# MMCSD0_COMMON_0_CTL_CFG register map
Vendor: Texas Instruments
Registers are 16-bit, read-write, reset 0x0 unless marked. A register's access mark holds for its fields unless they carry their own. Offsets are as the file gives them; [hi:lo] are bit positions; 'fields as' and 'values as' point back to an identical list.

## MMCSD0_COMMON_0_CTL_CFG (part 2 of 3)
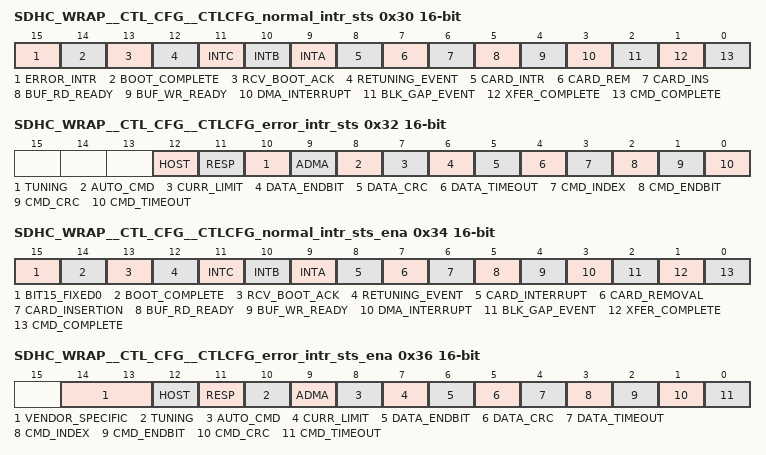
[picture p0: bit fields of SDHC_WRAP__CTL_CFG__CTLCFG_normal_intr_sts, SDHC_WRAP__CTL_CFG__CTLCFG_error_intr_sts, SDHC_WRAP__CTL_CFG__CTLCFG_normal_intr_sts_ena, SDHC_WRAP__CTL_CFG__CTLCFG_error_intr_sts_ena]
0x30 SDHC_WRAP__CTL_CFG__CTLCFG_normal_intr_sts access not given
  [15] ERROR_INTR ro — If any of the bits in the Error Interrupt Status Register are set, then this bit is set. Therefore the HD can test for an error by checking this bit first. In UHS-II mode is enabled, if any of the bits in the UHS-II Error Interrupt Status register are set, this bit is also set. '0' No error '1' Error
  [14] BOOT_COMPLETE — This status is set if the boot operation gets terminated. '0' Boot operation is not terminated '1' Boot operation is terminated (access R/W1TC)
  [13] RCV_BOOT_ACK — This status is set if the boot acknowledge is received from device. '0' Boot ack not recieved '1' Boot ack is recieved (access R/W1TC)
  [12] RETUNING_EVENT ro — This status is set if Re-Tuning Request in the Present State register changes from 0 to 1. Host Controller requests Host Driver to perform re-tuning for next data transfer. Current data transfer [not large block count] can be completed without re-tuning.In UHS-II mode, this bit is not effective '0' Re-tuning not required '1' Re-tuning should be performed
  [11] INTC ro — This status is set if INT_C is enabled and INT_C# pin is in low level. Writing this bit to 1 does not clear this bit. It is cleared by resetting the INT_C interrupt factor.
  [10] INTB ro — This status is set if INT_B is enabled and INT_B# pin is in low level. Writing this bit to 1 does not clear this bit. It is cleared by resetting the INT_B interrupt factor.
  [9] INTA ro — This status is set if INT_A is enabled and INT_A# pin is in low level. Writing this bit to 1 does not clear this bit. It is cleared by resetting the INT_A interrupt factor. NOTE : INT_A, INT_B, and INT_C are to be implemented based on the Application Requirements. By default these are not implemented as there is no specific requirement from Customers.
  [8] CARD_INTR ro — When this status has been set and the Host Driver needs to start this interrupt service, Card Interrupt Status Enable in the Normal Interrupt Status Enable register may be set to 0 in order to clear the card interrupt status latched in the Host Controller and to stop driv-ing the interrupt signal to the Host System.After completion of the card interrupt service [It should reset interrupt factors in the SD card and the interrupt signal may not be asserted],set Card Interrupt Status Enable to 1 and start sampling the interrupt signal again. Writing this bit to 1 does not clear this bit. It is cleared by resetting the SD card interrupt fac-tor. [1] DAT[1] Interrupt Input in SD Mode In 1-bit mode, the Host Controller shall detect the Card Interrupt without SD Clock to support wakeup. In 4-bit mode, the card interrupt sig-nal is sampled during the interrupt cycle, so there are some sample delays between the interrupt signal from the SD card and the inter-rupt to the Host System. Interrupt detected by DAT[1] is supported when there is a card per slot. In case of UHS-I mode, switching time of Interrupt Period is relaxed for 2 clock cycles. Then Host Controller needs to delay start of interrupt sampling at least 2 clocks and should sample interrupt while Interrupt Period is sta-ble. [2] DAT[2] Interrupt Input in UHS-II Mode When Card Inserted in the Present State reg-ister and SD Bus Power for VDD1 in the Power Control register are set to 1, Host Con-troller configures DAT[2] as Interrupt Input and enables pull-up of DAT[2]. DAT[2] interrupt is asynchronous to RCLK, low level sensitive and 3.3V signal level. DAT[2] interrupt is masked by setting Card Interrupt Status Enable to 0 in the Normal Interrupt register.When either Card Inserted or SD Bus Power for VDD1 is set to 0, Host Controller sets DAT[2] to low. Only point to point connection is allowed between Host and Card. [3] INT MSG in UHS-II Mode INT MSG is enabled by setting INT MSG Enable in the UHS-II Device Select register. DAT[2] and INT MSG interrupt sources are ORed and indicated to Card Interrupt. If any bit in the UHS-II Device Interrupt Status regis- ter is set to 1, INT MSG interrupt is generated. INT MSG interrupt is cleared by writing a cor-respondent bit to 1 in the UHS-II Device Inter-rupt Status register. Masking DAT[2] interrupt also disables INT MSG interupt due to Card Interrupt Status Enable is set to 0. SDIO Ver-sion 4.00 does not support INT MSG. '0' No Card Interrupt '1' Generate Card Interrupt
  [7] CARD_REM — This status is set if the Card Inserted in the Present State register changes from 1 to 0. When the HD writes this bit to 1 to clear this status the status of the Card Inserted in the Present State register should be confirmed. Because the card detect may possibly be changed when the HD clear this bit an Interrupt event may not be generated. '0' Card State Stable or Debouncing '1' Card Removed (access R/W1TC)
  [6] CARD_INS — This status is set if the Card Inserted in the Present State register changes from 0 to 1.When the HD writes this bit to 1 to clear this status the status of the Card Inserted in the Present State register should be confirmed. Because the card detect may possibly be changed when the HD clear this bit an Interrupt event may not be generated. '0' Card State Stable or Debouncing '1' Card Inserted (access R/W1TC)
  [5] BUF_RD_READY — This status is set if the Buffer Read Enable changes from 0 to 1. Buffer Read Ready is set to 1 for every CMD19 execution in tuning procedure.In UHS-II mode, this bit is set at FC [Flow Control] unit basis. '0' Not ready to read buffer, '1' Ready to read buffer (access R/W1TC)
  [4] BUF_WR_READY — This status is set if the Buffer Write Enable changes from 0 to 1.In UHS-II mode, this bit is set at FC [Flow Control] unit basis. '0' Not ready to write to buffer, '1' Ready to write to buffer (access R/W1TC)
  [3] DMA_INTERRUPT — This status is set if the HC detects the Host DMA Buffer Boundary in the Block Size regiser. '0' No DMA Interrupt '1' DMA Interrupt is generated (access R/W1TC)
  [2] BLK_GAP_EVENT — If the Stop At Block Gap Request in the BlockGap Control Register is set, this bit is set. Read Transaction: This bit is set at the falling edge of the DAT Line Active Status [When the transaction is stopped at SD Bus timing. The Read Wait must be supported inorder to use this function]. Write Transaction: This bit is set at the falling edge of Write Transfer Active Status [After getting CRC status at SD Bus timing]. In UHS-II mode, this bit is set at FC [Flow Control] unit basis. '0' No Block Gap Event '1' Transaction stopped at Block Gap (access R/W1TC)
  [1] XFER_COMPLETE — This bit is set when a read / write transaction is completed. SD Mode Read Transaction: This bit is set at the falling edge of Read Transfer Active Status. There are two cases in which the Interrupt is generated. The first is when a data transfer is completed as specified by data length [After the last data has been read to the Host Sys- tem]. The second is when data has stopped at the block gap and completed the data transfer by setting the Stop At Block Gap Request in the Block Gap Control Register [After valid data has been read to the Host System]. Write Transaction: This bit is set at the falling edge of the DAT Line Active Status. There are two cases in which the Interrupt is generated. The first is when the last data is written to the card as specified by data length and Busy signal is released. The second is when data transfers are stopped at the block gap by setting Stop At Block Gap Request in the Block Gap Control Register and data transfers completed. [After valid data is written to the SD card and the busy signal is released]. Note: Transfer Complete has higher priority than Data Time-out Error. If both bits are set to 1, the data transfer can be considered complete. Note: While performing tuning procedure [Execute Tuning is set to 1], Transfer Complete is not set to 1 Command with Busy: This bit is set when busy is de-asserted. Refer to DAT Line Active and Command Inhibit[DAT] in the Present State register.UHS-I mode While performing tuning procedure [Execute Tuning is set to 1], Transfer Complete is not set to 1. '0' No Data Transfer Complete, '1' Data Transfer Complete UHS-II Mode This interrupt is generated in following twocases: [a] EBSY Completion [for EBSY supported commands] When EBSY Wait in the UHS-II Transfer Mode register is set to 1, this bit is set when EBSY packet has been received, and all valid data have been sent to system memory in case of read operation. [b] Stop and Continue during DCMD Data Transfer When Stop At Block Gap Request in the Block Gap Control register is set to 1 and data transfer is stopped at the Flow Control. Following is for both SD mode and UHS-II mode. The table below shows that Transfer Com-plete has higher priority than Data Timeout Error. If both bits are set to 1, execution of a command can be considered to be completed. 1 - Command execution is completed 0 - Not complete (access R/W1TC)
  [0] CMD_COMPLETE — SD Mode This bit is set when we get the end bit of the command response [Except Auto CMD12 and Auto CMD23] Note: Command Time-out Error has higher priority than Command Complete. If both are set to 1, it can be considered that the response was not received correctly. Version 4.00 defines response check function for R1 and R5. If Response Interrupt Disable in the Transfer Mode register is set to 1, gen-eration of this interrupt is prohibited regardless of Command Complete Signal Enable. UHS-II Mode If Response Interrupt Disable is set to 0 in the UHS-II Transfer Mode register, this interrupt is generated when response packet is received.If Response Interrupt Disable is set to 1 in the UHS-II Transfer Mode register, generation of this interrupt is prohibited regardless of Com-mand Complete Signal Enable. '0' No Command Complete, '1' Command Complete (access R/W1TC)
0x32 SDHC_WRAP__CTL_CFG__CTLCFG_error_intr_sts access not given
  [12] HOST — Occurs when detecting ERROR in m_hresp[dma transaction] (access R/W1TC)
  [11] RESP — Host Controller Version 4.00 supports response error check function to avoid overhead of response error check by Host Driver during DMA execution. If Response Error Check Enable is set to 1 in the Transfer Mode register, Host Controller Checks R1 or R5 response. If an error is detected in a response, this bit is set to 1.If Response Error Check Enable is set to 1 in the Transfer Mode register, Host Controller Checks R1 or R5 response. (access R/W1TC)
  [10] TUNING — This bit is set when an unrecoverable error is detected in a tuning circuit except during tuning procedure [Occurrence of an error during tuning procedure is indicated by Sampling Select]. By detecting Tuning Error, Host Driver needs to abort a command executing and perform tuning.To reset tuning circuit, Sampling Clock shall be set to 0 before executing tuning procedure. The Tuning Error is higher priority than the other error interrupts generated during data transfer. By detecting Turning Error, the Host Driver should discard data transferred by a current read/write command and retry data transfer after the Host Controller retrieved from tuning circuit error. (access R/W1TC)
  [9] ADMA — This bit is set when the Host Controller detects errors during ADMA based data transfer. The state of the ADMA at an error occurrence is saved in the ADMA Error Status Register. (access R/W1TC)
  [8] AUTO_CMD — Auto CMD12 and Auto CMD23 use this error status.This bit is set when detecting that any of the bits D00 to D05 in Auto CMD Error Status register has changed from 0 to 1. D07 is effective in case of Auto CMD12. Auto CMD Error Status register is valid while this bit is set to 1 and may be cleared with clearing of this bit [another implementation is also allowed]. (access R/W1TC)
  [7] CURR_LIMIT — By setting the SD Bus Power bit in the Power Control Register, the HC is requested to supply power for the SD Bus. If the HC supports the Current Limit Function, it can be protected from an Illegal card by stopping power supply to the card in which case this bit indicates a failure status. Reading 1 means the HC is not supplying power to SD card due to some failure. Reading 0 means that the HC is supplying power and no error has occurred. This bit shall always set to be 0, if the HC does not support this function. (access R/W1TC)
  [6] DATA_ENDBIT — Occurs when detecting 0 at the end bit position of read data which uses the DAT line or the end bit position of the CRC status. (access R/W1TC)
  [5] DATA_CRC — Occurs when detecting CRC error when transferring read data which uses the DAT line or when detecting the Write CRC Status having a value of other than 010. (access R/W1TC)
  [4] DATA_TIMEOUT — Occurs when detecting one of following timeout conditions: 1. Busy Timeout for R1b, R5b type. 2. Busy Timeout after Write CRC status 3. Write CRC status Timeout 4. Read Data Timeout. (access R/W1TC)
  [3] CMD_INDEX — Occurs if a Command Index error occurs in the Command Response. (access R/W1TC)
  [2] CMD_ENDBIT — Occurs when detecting that the end bit of a command response is 0. (access R/W1TC)
  [1] CMD_CRC — Command CRC Error is generated in two cases. 1. If a response is returned and the Command Time-out Error is set to 0, this bit is set to 1 when detecting a CRT error in the command response 2. The HC detects a CMD line conflict by monitoring the CMD line when a command is issued. If the HC drives the CMD line to 1 level, but detects 0 level on the CMD line at the next SDCLK edge, then the HC shall abort the command [Stop driving CMD line] and set this bit to 1. The Command Timeout Error shall also be set to 1 to distinguish CMD line conflict. (access R/W1TC)
  [0] CMD_TIMEOUT — Occurs only if the no response is returned within 64 SDCLK cycles from the end bit of the command. If the HC detects a CMD line conflict, in which case Command CRC Error shall also be set. This bit shall be set without waiting for 64 SDCLK cycles because the command will be aborted by the HC. (access R/W1TC)
0x34 SDHC_WRAP__CTL_CFG__CTLCFG_normal_intr_sts_ena access per field
  [15] BIT15_FIXED0 ro — The HC shall control error Interrupts using the Error Interrupt Status Enable register.
  [14] BOOT_COMPLETE rw — '0' Masked '1' Enabled
  [13] RCV_BOOT_ACK rw — '0' Masked '1' Enabled
  [12] RETUNING_EVENT rw — 0 - Masked 1 - Enabled
  [11] INTC rw — If this bit is set to 0, the Host Controller shall clear the interrupt request to the System. The Host Driver may clear this bit before servicing the INT_C and may set this bit again after all interrupt requests to INT_C pin are cleared to prevent inadvertent interrupts.
  [10] INTB rw — If this bit is set to 0, the Host Controller shall clear the interrupt request to the System. The Host Driver may clear this bit before servicing the INT_B and may set this bit again after all interrupt requests to INT_B pin are cleared to prevent inadvertent interrupts.
  [9] INTA rw — If this bit is set to 0, the Host Controller shall clear the interrupt request to the System. The Host Driver may clear this bit before servicing the INT_A and may set this bit again after all interrupt requests to INT_A pin are cleared to prevent inadvertent interrupts.
  [8] CARD_INTERRUPT rw — If this bit is set to 0, the HC shall clear Interrupt request to the System. The Card Interrupt detection is stopped when this bit is cleared and restarted when this bit is set to 1. The HD may clear the Card Interrupt Status Enable before servicing the Card Interrupt and may set this bit again after all Interrupt requests from the card are cleared to prevent inadvertent Interrupts. By setting this bit to 0, interrupt input should be masked by implementation so that the interrupt Input is not affected by external signal in any state [ex. floating].
  [7] CARD_REMOVAL rw — '0' Masked '1' Enabled
  [6] CARD_INSERTION rw — '0' Masked '1' Enabled
  [5] BUF_RD_READY rw — '0' Masked '1' Enabled
  [4] BUF_WR_READY rw — '0' Masked '1' Enabled
  [3] DMA_INTERRUPT rw — '0' Masked, '1' Enabled
  [2] BLK_GAP_EVENT rw — '0' Masked '1' Enabled
  [1] XFER_COMPLETE rw — '0' Masked '1' Enabled
  [0] CMD_COMPLETE rw — '0' Masked '1' Enabled
0x36 SDHC_WRAP__CTL_CFG__CTLCFG_error_intr_sts_ena
  [14:13] VENDOR_SPECIFIC
  [12] HOST — '0' Masked '1' Enabled
  [11] RESP — '0' Masked '1' Enabled
  [10] TUNING — '0' Masked '1' Enabled
  [9] ADMA — '0' Masked '1' Enabled
  [8] AUTO_CMD — '0' Masked '1' Enabled
  [7] CURR_LIMIT — '0' Masked '1' Enabled
  [6] DATA_ENDBIT — '0' Masked '1' Enabled
  [5] DATA_CRC — '0' Masked '1' Enabled
  [4] DATA_TIMEOUT — '0' Masked '1' Enabled
  [3] CMD_INDEX — '0' Masked '1' Enabled
  [2] CMD_ENDBIT — '0' Masked '1' Enabled
  [1] CMD_CRC — '0' Masked '1' Enabled
  [0] CMD_TIMEOUT — '0' Masked '1' Enabled
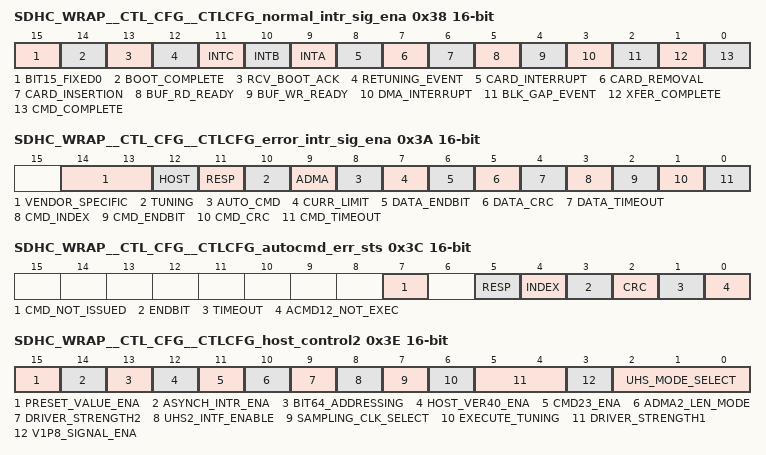
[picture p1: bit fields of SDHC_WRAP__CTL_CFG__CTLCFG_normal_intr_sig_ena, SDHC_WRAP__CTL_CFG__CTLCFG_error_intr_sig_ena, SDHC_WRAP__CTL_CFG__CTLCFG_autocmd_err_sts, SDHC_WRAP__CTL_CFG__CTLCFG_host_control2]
0x38 SDHC_WRAP__CTL_CFG__CTLCFG_normal_intr_sig_ena access per field
  [15] BIT15_FIXED0 ro — The HD shall control error Interrupts using the Error Interrupt Signal Enable register.
  [14] BOOT_COMPLETE rw — '0' Masked '1' Enabled
  [13] RCV_BOOT_ACK rw — '0' Masked '1' Enabled
  [12] RETUNING_EVENT rw — '0' Masked '1' Enabled
  [11] INTC rw — '0' Masked '1' Enabled
  [10] INTB rw — '0' Masked '1' Enabled
  [9] INTA rw — '0' Masked '1' Enabled
  [8] CARD_INTERRUPT rw — '0' Masked '1' Enabled
  [7] CARD_REMOVAL rw — '0' Masked '1' Enabled
  [6] CARD_INSERTION rw — '0' Masked '1' Enabled
  [5] BUF_RD_READY rw — '0' Masked '1' Enabled
  [4] BUF_WR_READY rw — '0' Masked '1' Enabled
  [3] DMA_INTERRUPT rw — '0' Masked '1' Enabled
  [2] BLK_GAP_EVENT rw — '0' Masked '1' Enabled
  [1] XFER_COMPLETE rw — '0' Masked '1' Enabled
  [0] CMD_COMPLETE rw — '0' Masked '1' Enabled
0x3A SDHC_WRAP__CTL_CFG__CTLCFG_error_intr_sig_ena
  fields as SDHC_WRAP__CTL_CFG__CTLCFG_error_intr_sts_ena
0x3C SDHC_WRAP__CTL_CFG__CTLCFG_autocmd_err_sts ro
  [7] CMD_NOT_ISSUED — Setting this bit to 1 means CMD_wo_DAT is not executed due to an Auto CMD12 error [D04- D01] in this register. This bit is set to 0 when Auto CMD Error is generated by Auto CMD23.
  [5] RESP — This bit is set when Response Error Check Enable in the Transfer Mode register is set to 1 and an error is detected in R1 response of either Auto CMD12 or Auto CMD23. This status should be ignored if any bit of D00 to D04 is set to 1.
  [4] INDEX — Occurs if the Command Index error occurs in response to a command.
  [3] ENDBIT — Occurs when detecting that the end bit of command response is 0.
  [2] CRC — Occurs when detecting a CRC error in the command response.
  [1] TIMEOUT — Occurs if the no response is returned within 64 SDCLK cycles from the end bit of the command.If this bit is set to 1, the other error status bits [D04 - D02] are meaningless.
  [0] ACMD12_NOT_EXEC — If memory multiple block data transfer is not started due to command error, this bit is not set because it is not necessary to issue Auto CMD12. Setting this bit to 1 means the HC cannot issue Auto CMD12 to stop memory multiple block transfer due to some error. If this bit is set to 1, other error status bits [D04 - D01] are meaningless. This bit is set to 0 when Auto CMD Error is generated by Auto CMD23
0x3E SDHC_WRAP__CTL_CFG__CTLCFG_host_control2
  [15] PRESET_VALUE_ENA — Host Controller Version 3.00 supports this bit. As the operating SDCLK frequency and I/O driver strength depend on the Host System implementation, it is difficult to determine these parameters in the Standard Host Driver. When Preset Value Enable is set to automatic. This bit enables the functions defined in the Preset Value registers. If this bit is set to 0, SDCLK Frequency Select, Clock Generator Select in the Clock Control register and Driver Strength Select in Host Control 2 register are set by Host Driver. If this bit is set to 1, SDCLK Frequency Select, Clock Generator Select in the Clock Control register and Driver Strength Select in Host Control 2 register are set by Host Controller as specified in the Preset Value registers.
  [14] ASYNCH_INTR_ENA — This bit can be set to 1 if a card support asynchronous interrupt and Asynchronous Interrupt Support is set to 1 in the Capabilities register. Asynchronous interrupt is effective when DAT[1] interrupt is used in 4-bit SD mode [and zero is set to Interrupt Pin Select in the Shared Bus Control register]. If this bit is set to 1, the Host Driver can stop the SDCLK during asynchronous interrupt period to save power. During this period, the Host Controller continues to deliver Card Interrupt to the host when it is asserted by the Card.
  [13] BIT64_ADDRESSING — This field is effective when Host Version 4.00 Enable is set to 1. Host Controller selects either of 32-bit or 64-bit addressing modes to access system memory. Whether 32-bit or 64-bit is determined by OS installed in a host system. Host Driver sets this bit depends on addressing mode of installed OS. Refer to 64-bit System Address Support in the Capabilities register. .
  [12] HOST_VER40_ENA — This bit selects either Version 3.00 compatible mode or Ver4.mode. In Version 4.00, support of 64-bit System Addressing is modified. All DMAs support 64-bit System Addressing. UHS-II supported Host Driver shall enable this bit. In Version 4.10, supported 32-bit Block Count for all operations. Functions of following fields are modified. SDMA Address SDMA uses ADMA System Address register [05Fh-058h] instead of SDMA System Address register [Offset 003-000h] ADMA2 / ADMA3 Selection ADMA3 is selected by DMA Select in the Host Control 1 regis-ter. 64bit ADMA Descriptor Size 128bit descriptor is used instead of 96-bit descriptor when 64-bit Addressing is set to 1. Selection of 32-bit / 64-bit System Addressing Either 32-bit or 64-bit system addressing is selected by 64-bit Addressing bit in this register instead of DMA Select in the Host Control 1 register. 32-bit Block Count SDMA System Address register [003h-000h] is modified to 32-bit Block Count register.
  [11] CMD23_ENA — In memory card initialization, Host Driver Version 4.10 checks whether card supports CMD23 by checking a bit SCR[33]. If the card supports CMD23 [SCR[33]=1], this bit is set to 1. This bit is used to select Auto CMD23 or Auto CMD12 for ADMA3 datatransfer. Refer to Auto CMD Enable in the Transfer Mode regis-ter.
  [10] ADMA2_LEN_MODE — This bit selects one of ADMA2 Length Modes either 16-bit or 26-bit.
  [9] DRIVER_STRENGTH2 — This is the programmed Drive STrength output and Bit[2] of the sdhccore_drivestrength value.
  [8] UHS2_INTF_ENABLE — This bit is used to enable UHS-II Interface. Before trying to start UHS-II initialization, this bit shall be set to 1. Before trying to start SD mode initialization, this bit shall be set to 0. This bit is used to enable UHS-II IF Detection, Lane Synchroni-zation and In Dormant State in the Present State register, and to select clock source of either SD mode or UHS-II mode. Host Controller shall not leave unused SD 4-bit Interface lines [CLK, CMD and DAT[3:2]] floating in UHS-II mode by using pull-up or driving to low. When DAT[2] is used as interrupt input in UHS-II mode, DAT[2] of Host Controller is set to input and then DAT[2] of SDIO card is set to output to avoid conflict. '0' 4-bit SD Interface enabled '1' UHS-II Interface enabled
  [7] SAMPLING_CLK_SELECT — This bit is set by tuning procedure when Execute Tuning is cleared. Writing 1 to this bit is meaningless and ignored. Setting 1 means that tuning is completed successfully and setting 0 means that tuning is failed. Host Controller uses this bit to select sampling clock to receive CMD and DAT. This bit is cleared by writing 0. Change of this bit is not allowed while the Host Controller is receiving response or a read data block.
  [6] EXECUTE_TUNING — This bit is set to 1 to start tuning procedure and automatically cleared when tuning procedure is completed. The result of tuning is indicated to Sampling Clock Select. Tuning procedure is aborted by writing 0 for more detail about tuning procedure. '0' Not Tuned or Tuning Completed '1' Execute Tuning
  [5:4] DRIVER_STRENGTH1 — Host Controller output driver in 1.8V signaling is selected by this bit. In 3.3V signaling, this field is not effective. This field can be set depends on Driver Type A, C and D support bits in the Capabilities register. This bit depends on setting of Preset Value Enable. If Preset Value Enable = 0, this field is set by Host Driver. If Preset Value Enable = 1, this field is automatically set by a value specified in the one of Preset Value registers.
  [3] V1P8_SIGNAL_ENA — This bit controls voltage regulator for I/O cell. 3.3V is supplied to the card regardless of signaling voltage. Setting this bit from 0 to 1 starts changing signal voltage from 3.3V to 1.8V. 1.8V regulator output shall be stable within 5ms. Host Controller clears this bit if switching to 1.8V signaling fails. Clearing this bit from 1 to 0 starts changing signal voltage from 1.8V to 3.3V. 3.3V regulator output shall be stable within 5ms. Host Driver can set this bit to 1 when Host Controller supports 1.8V signaling [One of support bits is set to 1: SDR50, SDR104 or DDR50 in the Capabilities register] and the card or device supports UHS-I. '0' 3.3V Signalling, '1' 1.8V Signalling
  [2:0] UHS_MODE_SELECT — This field is used to select one of UHS-I modes or UHS-II mode.In case of UHS-I mode, this field is effective when 1.8V Signal-ing Enable is set to 1. In case of UHS-II mode, 1.8V Signaling Enable shall be set to 0. Setting of this field is used to select one of preset values in UHS-I or UHS-II mode. If Preset Value Enable in the Host Control 2 register is set to 1,Host Controller sets SDCLK/RCLK Frequency Select, Clock Generator Select in the Clock Control register and Driver Strength Select according to Preset Value registers. In this case, one of preset value registers is selected by this field. Host Driver needs to reset SD Clock Enable before changing this field to avoid generating clock glitch. After setting this field, Host Driver sets SD Clock Enable again. When SDR50, SDR104 or DDR50 is selected for SDIO card, interrupt detection at the block gap shall not be used. Read Wait timing is changed for these modes. Refer to the SDIO Specification Version 3.00 for more detail.
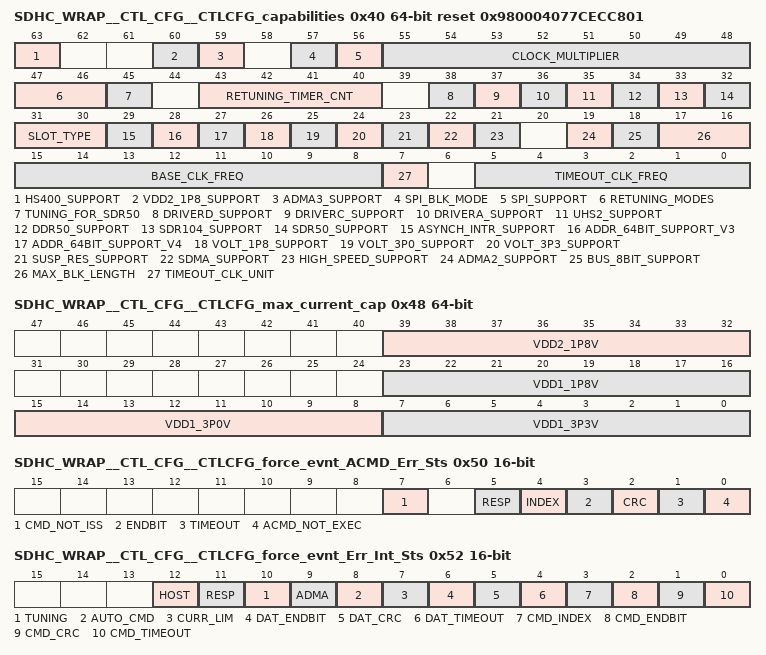
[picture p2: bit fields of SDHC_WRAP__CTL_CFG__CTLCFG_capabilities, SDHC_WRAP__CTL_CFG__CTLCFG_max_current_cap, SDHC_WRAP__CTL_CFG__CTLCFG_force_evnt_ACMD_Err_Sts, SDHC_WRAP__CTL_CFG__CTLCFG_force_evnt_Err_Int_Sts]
0x40 SDHC_WRAP__CTL_CFG__CTLCFG_capabilities 64-bit ro reset 0x980004077CECC801
  [63] HS400_SUPPORT — 1 HS400 is Supported 0 HS400 is Not Supported
  [60] VDD2_1P8_SUPPORT — This field indicates that support of VDD2 on Host system.
  [59] ADMA3_SUPPORT — This field indicates that support of ADMA3 on Host Controller.
  [57] SPI_BLK_MODE — This field indicates whether SPI Block Mode is supported or not.
  [56] SPI_SUPPORT — This field indicates whether SPI Mode is supported or not.
  [55:48] CLOCK_MULTIPLIER — This field indicates clock multiplier value of programmable clock generator. Refer to Clock Control register. Setting 00h means that Host Controller does not support programmable clock generator. 'FF' Clock Multiplier M = 256 --------- '02' Clock Multiplier M = 3 '01' Clock Multiplier M = 2 '00' Clock Multiplier is Not Supported.
  [47:46] RETUNING_MODES — This field defines the re-tuning capability of a Host Controller and how to manage the data transfer length and a Re-Tuning Timer by the Host Driver. '00' Mode 1 '01' Mode 2 '10' Mode 3 '11' Reserved. There are two re-tuning timings:Re-Tuning Request and expiration of a Re-Tuning Timer. By receiving either timing, the Host Driver executes the re-tuning procedure just before a next command issue.
  [45] TUNING_FOR_SDR50 — If this bit is set to 1, this Host Controller requires tuning to operate SDR50. [Tuning is always required to operate SDR104]. '0' '1'
  [43:40] RETUNING_TIMER_CNT — This field indicates an initial value of the Re-Tuning Timer for Re-Tuning Mode 1 to 3. 0h - Get information via other source 1h = 1 seconds 2h = 2 seconds 3h = 4 seconds 4h = 8 seconds ------ n = 2[n-1] seconds ------ Bh = 1024 seconds Fh - Ch = Reserved
  [38] DRIVERD_SUPPORT — This bit indicates support of Driver Type D for 1.8 Signaling. '0' Driver Type D is Not supported, '1' Driver Type D is supported
  [37] DRIVERC_SUPPORT — This bit indicates support of Driver Type C for 1.8 Signaling. '0' Driver Type C is Not supported, '1' Driver Type C is supported
  [36] DRIVERA_SUPPORT — This bit indicates support of Driver Type A for 1.8 Signaling. '0' Driver Type A is Not supported, '1' Driver Type A is supported
  [35] UHS2_SUPPORT — This bit indicates whether Host controller supports UHS-II. If this bit is set to 1, 1.8V VDD2 Support shall be set to 1 [Host Sys- tem shall support VDD2 power supply]. 1 UHS-II is Supported 0 UHS-II is Not Supported
  [34] DDR50_SUPPORT — This bit indicates whether DDR50 is supported or not.
  [33] SDR104_SUPPORT — This bit indicates whether SDR104 is supported or not.SDR104 requires tuning.
  [32] SDR50_SUPPORT — If SDR104 is supported, this bit shall be set to 1. Bit 40 indicates whether SDR50 requires tuning or not.
  [31:30] SLOT_TYPE — This field indicates usage of a slot by a specific Host System. [A host controller register set is defined perslot.] Embedded slot for one device [01b] means that only one non-removable device is connected to a SD bus slot. Shared Bus Slot [10b] can be set if Host Controller supports Shared Bus Control register. The Standard Host Driver controls only a removable card or one embedded device is connected to a SD bus slot. If a slot is configured for shared bus [10b], the Standard Host Driver does not control embedded devices connected to a shared bus. Shared bus slot is controlled by a specific host driver developed by a Host System.
  [29] ASYNCH_INTR_SUPPORT — Refer to SDIO Specification Version 3.00 about asynchronous interrupt.
  [28] ADDR_64BIT_SUPPORT_V3 — IMeaning of this bit is different depends on Versions [Refer to Table 2-35 for more details]. Host Controller Version 3.00 and Ver4.10 use this bit as 64-bit System Address support for V3 mode. Host Con- troller Version 4.00 uses this bit as 64-bit System Address support for both V3 and V4 modes. SDMA cannot be used in 64-bit Address-ing in Version 3 mode. If this bit is set to 1, 64-bit ADMA2 with using 96-bit Descriptor may be enabled as follows: In case of Host Controller Version 3, 64-bit ADMA2 is enabled by DMA Select =11b in the Host Control 1 register. In case of Host Controller Version 4, 64-bitADMA2 for Version 3 is enabled by setting Host Version 4 Enable =0 and DMA Select = 11b. 1 - 64-bit System Address for V3 is Supported 0 - 64-bit System Address for V3 is not Supported
  [27] ADDR_64BIT_SUPPORT_V4 — This bit is added from Version 4.10. Set-ting 1 to this bit indicates that the Host Controller supports 64-bit System Addressing of Version 4 mode [Refer to Table 2-35 for the summary of 64-bit sys-tem address support].. When this bit is set to 1, full or a part of 64-bit address should be used to decode Host Controller Registers so that Host Controller Registers can be placed above system memory area. 64-bit address decode of Host Controller Registers is effective regardless of setting to 64bit Addressing in Host Control 2. If this bit is set to 1, 64-bit DMA Address-ing for Version 4 is enabled by setting Host Version 4 Enable =1, 64-bit Address-ing =1 in the Host Control 2 register.SDMA can be used and ADMA2 uses 128-bit Descriptor.
  [26] VOLT_1P8_SUPPORT — This bit indicates whether the HC supports 1.8V.
  [25] VOLT_3P0_SUPPORT — This bit indicates whether the HC supports 3.0V.
  [24] VOLT_3P3_SUPPORT — This bit indicates whether the HC supports 3.3V.
  [23] SUSP_RES_SUPPORT — This bit indicates whether the HC supports Suspend / Resume functionality. If this bit is 0, the Suspend and Resume mechanism are not supported and the HD shall not issue either Suspend / Resume commands.
  [22] SDMA_SUPPORT — This bit indicates whether the HC is capable of using DMA to transfer data between system memory and the HC directly.Version 4.10 Host Controller shall support SDMA if ADMA2 is supported.
  [21] HIGH_SPEED_SUPPORT — This bit indicates whether the HC and the Host System support High Speed mode and they can supply SD Clock frequency from 25Mhz to 50 Mhz [for SD]/ 20MHz to 52MHz [for MMC].
  [19] ADMA2_SUPPORT — '0' ADMA2 Not Supported '1' ADMA2 Supported
  [18] BUS_8BIT_SUPPORT — This bit indicates whether the Host Controller is capable of using 8-bit bus width mode. This bit is not effective when Slot Type is set to 10b. In this case, refer to Bus Width Preset in the Shared Bus resister.
  [17:16] MAX_BLK_LENGTH — This value indicates the maximum block size that the HD can read and write to the buffer in the HC. The buffer shall transfer this block size without wait cycles. Three sizes can be defined as indicated below.
  [15:8] BASE_CLK_FREQ — [1]6-bit Base Clock Frequency: This mode is supported by the Host Controller Version 1.00 and 2.00. Upper 2-bit is not effective and always 0. Unit values are 1MHz. The supported clock range is 10MHz to 63MHz. '11xx xxxxb' Not Supported '0011 1111b' 63MHz '0000 0010b' 2MHz '0000 0001b' 1MHz '0000 0000b'Get Information via another method [2]8-bit Base Clock Frequency: This mode is supported by the Host Controller Version 3.00.Unit values are 1MHz. The supported clock range is 10MHz to 255MHz. 'FFh' 255MHz '02h' 2MHz '01h' 1MHz '00h' Get Information via another method. If the real frequency is 16.5MHz, the lager value shall be set 0001 0001b [17MHz] because the Host Driver use this value to calculate the clock divider value [Refer to the SDCLK Frequency Select in the Clock Control register.] and it shall not exceed upper limit of the SD Clock frequency. If these bits are all 0, the Host System has to get information via another method.
  [7] TIMEOUT_CLK_UNIT — This bit shows the unit of base clock frequency used to detect Data Timeout Error.
  [5:0] TIMEOUT_CLK_FREQ — This bit shows the base clock frequency used to detect Data Timeout Error. '000000' Get Information via another method, 'not 0' 1KHz to 63KHz/1MHz to 63MHz
0x48 SDHC_WRAP__CTL_CFG__CTLCFG_max_current_cap 64-bit ro
  [39:32] VDD2_1P8V — Maximum Current for 1.8V VDD2
  [23:16] VDD1_1P8V — Maximum Current for 1.8V VDD1
  [15:8] VDD1_3P0V — Maximum Current for 3.0V VDD1
  [7:0] VDD1_3P3V — Maximum Current for 3.3V VDD1
0x50 SDHC_WRAP__CTL_CFG__CTLCFG_force_evnt_ACMD_Err_Sts wo
  [7] CMD_NOT_ISS — Force Event for Command Not Issued by AUTO CMD12 Error.
  [5] RESP — Force Event for AUTO CMD Response Error..
  [4] INDEX — Force Event for AUTO CMD Index Error..
  [3] ENDBIT — Force Event for AUTO CMD End Bit Error.
  [2] CRC — Force Event for AUTO CMD Timeout Error.
  [1] TIMEOUT — Force Event for AUTO CMD Timeout Error.
  [0] ACMD_NOT_EXEC — Force Event for AUTO CMD12 Not Executed.
0x52 SDHC_WRAP__CTL_CFG__CTLCFG_force_evnt_Err_Int_Sts wo
  [12] HOST — Force Event for Host Error
  [11] RESP — Force Event for Response Error
  [10] TUNING — Force Event for Tuning Error.
  [9] ADMA — Force Event for ADMA Error.
  [8] AUTO_CMD — Force Event for Auto CMD Error.
  [7] CURR_LIM — Force Event for Current Limit Error.
  [6] DAT_ENDBIT — Force Event for Data End Bit Error.
  [5] DAT_CRC — Force Event for Data CRC Error.
  [4] DAT_TIMEOUT — Force Event for Data Timeout Error.
  [3] CMD_INDEX — Force Event for Command Index Error
  [2] CMD_ENDBIT — Force Event for Command End Bit Error.
  [1] CMD_CRC — Force Event for Command CRC Error.
  [0] CMD_TIMEOUT — Force Event for CMD Timeout Error.
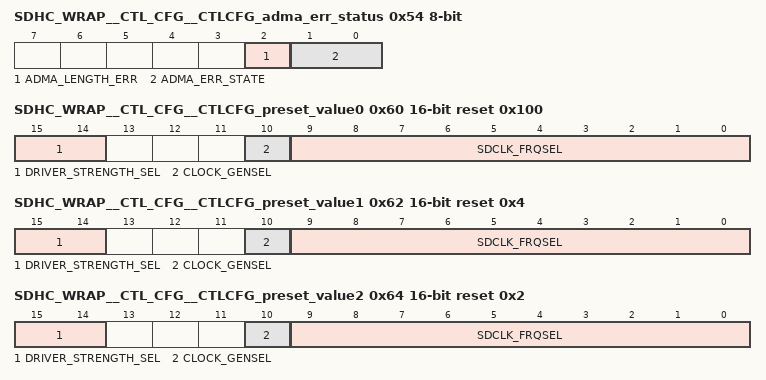
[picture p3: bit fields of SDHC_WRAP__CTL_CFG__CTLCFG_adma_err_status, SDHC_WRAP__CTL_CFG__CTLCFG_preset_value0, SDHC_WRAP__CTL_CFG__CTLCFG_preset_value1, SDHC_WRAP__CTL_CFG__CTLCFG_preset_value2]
0x54 SDHC_WRAP__CTL_CFG__CTLCFG_adma_err_status 8-bit ro
  [2] ADMA_LENGTH_ERR — This error occurs in the following 2 cases. While Block Count Enable being set, the total data length specified by the Descriptor table is different from that specified by the Block Count and Block Length. Total data length can not be divided by the block length.
  [1:0] ADMA_ERR_STATE — This field indicates the state of ADMA when error is occurred during ADMA data transfer. This field never indicates '10' because ADMA never stops in this state. D01 D00 : ADMA Error State when error occurred Contents of SYS_SDR register.
0x58 SDHC_WRAP__CTL_CFG__CTLCFG_adma_sys_address 64-bit
  [63:0] ADMA_ADDR — The 32-bit addressing Host Driver uses lower 32-bit of this register [upper 32-bit should be set to 0] and shall program Descriptor Table on 32-bit boundary andset 32-bit boundary address to this register. DMA2/3 ignores lower 2-bit of this register and assumes it to be 00b. DMA in 64-bit addressing. The 64-bit addressing Host Driver uses all bits of this register and shall program Descriptor Table on 64-bit boundary and set 64-bit boundary address to this register. DMA2/3 ignores lower 3-bit of this register andassumes it to be 000b. SDMA If Host Version 4.00 Enable is set to 1, SDMA use this register to indicate System Address of data location instead of using SDMA System Address register [Offset 003-000h]. SDMA can be used in 32-bit and 64-bit addressing in Version 4.00. ADMA2 This register holds byte address of executing command of the Descriptor table. At the start of ADMA2, the Host Driver shall set start address of the Descriptor table. The ADMA increments this register address, which points to next line, when every fetching a Descriptor line. When the ADMA Error Interrupt is generated, this register shall hold the Descriptor address depending on the ADMA state. ADMA3 This register is set by ADMA3. Host Driver is not necessary to set this register. The ADMA3 increments address of this register,which points to next line, when every time fetching a Descriptor line. When Error Interrupt is generated, this register shall hold the Descriptor address depending on the ADMA state. Register Value - 00000000_xxxxxxxxh Addressing Mode - 32-bit System Address Register Value - xxxxxxxx_xxxxxxxxh Addressing Mode - 64-bit System Address
0x60 SDHC_WRAP__CTL_CFG__CTLCFG_preset_value0 ro reset 0x100
  [15:14] DRIVER_STRENGTH_SEL — Driver Strength is supported by 1.8V signaling bus speed modes. This field is meaningless for 3.3V signaling.
  [10] CLOCK_GENSEL — This bit is effective when Host Controller supports programmable clock '0' Host Controller Ver2.00 Compatible Clock Generator '1' Programmable Clock Generator
  [9:0] SDCLK_FRQSEL — 10-bit preset value to set SDCLK Frequency Select in the Clock Control Register is described by a host system.
0x62 SDHC_WRAP__CTL_CFG__CTLCFG_preset_value1 ro reset 0x4
  fields as SDHC_WRAP__CTL_CFG__CTLCFG_preset_value0
0x64 SDHC_WRAP__CTL_CFG__CTLCFG_preset_value2 ro reset 0x2
  fields as SDHC_WRAP__CTL_CFG__CTLCFG_preset_value0
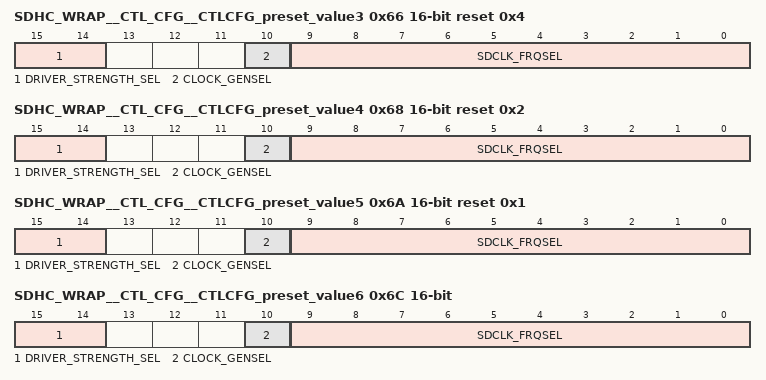
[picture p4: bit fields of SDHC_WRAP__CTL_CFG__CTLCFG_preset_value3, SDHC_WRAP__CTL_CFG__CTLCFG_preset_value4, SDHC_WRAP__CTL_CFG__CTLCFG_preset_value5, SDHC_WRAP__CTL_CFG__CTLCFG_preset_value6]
0x66 SDHC_WRAP__CTL_CFG__CTLCFG_preset_value3 ro reset 0x4
  fields as SDHC_WRAP__CTL_CFG__CTLCFG_preset_value0
0x68 SDHC_WRAP__CTL_CFG__CTLCFG_preset_value4 ro reset 0x2
  fields as SDHC_WRAP__CTL_CFG__CTLCFG_preset_value0
0x6A SDHC_WRAP__CTL_CFG__CTLCFG_preset_value5 ro reset 0x1
  fields as SDHC_WRAP__CTL_CFG__CTLCFG_preset_value0
0x6C SDHC_WRAP__CTL_CFG__CTLCFG_preset_value6 ro
  fields as SDHC_WRAP__CTL_CFG__CTLCFG_preset_value0
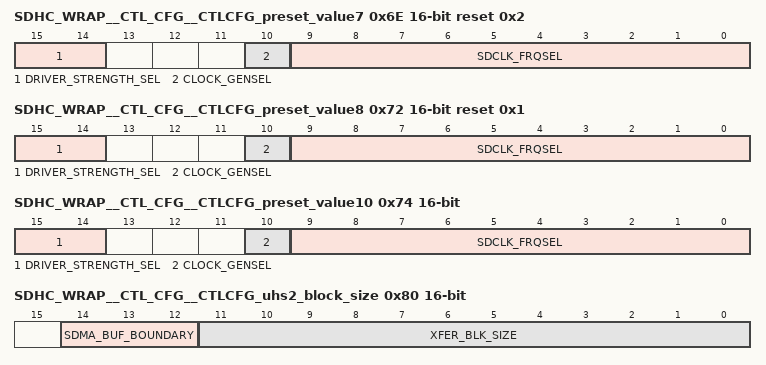
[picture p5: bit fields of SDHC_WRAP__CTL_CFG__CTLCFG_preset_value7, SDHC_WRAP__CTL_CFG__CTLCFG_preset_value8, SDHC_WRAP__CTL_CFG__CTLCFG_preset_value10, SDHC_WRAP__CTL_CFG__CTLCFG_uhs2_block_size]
0x6E SDHC_WRAP__CTL_CFG__CTLCFG_preset_value7 ro reset 0x2
  fields as SDHC_WRAP__CTL_CFG__CTLCFG_preset_value0
0x72 SDHC_WRAP__CTL_CFG__CTLCFG_preset_value8 ro reset 0x1
  fields as SDHC_WRAP__CTL_CFG__CTLCFG_preset_value0
0x74 SDHC_WRAP__CTL_CFG__CTLCFG_preset_value10 ro
  fields as SDHC_WRAP__CTL_CFG__CTLCFG_preset_value0
0x78 SDHC_WRAP__CTL_CFG__CTLCFG_adma3_desc_address 64-bit
  [63:0] INTG_DESC_ADDR — The start address of Integrated DMA Descriptor is set to this register. Writing to a specific address starts ADMA3 depends on 32-bit/64-bit address-ing. The ADMA3 fetches one Descriptor Address and increments this field to indicate the next Descriptor address. The 32-bit addressing Host Driver uses lower 32- bit of this register and shall program Descriptor Table on 32-bit boundary.ADMA3 ignores lower 2-bit of this register and assumes it to be 00b. Writing to 07Bh starts ADMA3 data transfer. The 64-bit addressing Host Driver uses all 64-bit of this register and shall program Descriptor Table on 64-bit boundary. ADMA3 ignores lower 3-bit of this register and assumes it to be 000b. Writing to 07Fh starts ADMA3 data transfer. Register Value- 00000000_xxxxxxxxh Addressing Mode - 32-bit System Address Register Value - xxxxxxxx_xxxxxxxxh Addressing Mode - 64-bit System Address
0x80 SDHC_WRAP__CTL_CFG__CTLCFG_uhs2_block_size
  [14:12] SDMA_BUF_BOUNDARY — When system memory is managed by paging, SDMA data transfer is performed in unit of paging. A page size of sys-tem memory management is set to this field. Host Controller generates the DMA Interrupt at the page boundary and requests the Host Driver to update the ADMA System Address register. SDMA waits until the ADMA System Address register is written. At the end of transfer, the Host Controller may issue or may not issue DMA Interrupt. In particular, DMA Interrupt shall not be issued after Transfer Complete Interrupt is issued. These bits shall be supported when the SDMA Support in the Capabilities register is set to 1 and this function is active when the DMA Enable in the UHS-II Transfer Mode register is set to 1. ADMA does not use this field.
  [11:0] XFER_BLK_SIZE — This register specifies the block size of data packet. SD Memory Card uses a fixed block size of 512 bytes. Vari-able block size may be used for SDIO. The maximum value is 2048 Bytes because CRC16 covers up to 2048 bytes. This register is effective when Data Present is set to 1 in UHS-II Command register.
0x84 SDHC_WRAP__CTL_CFG__CTLCFG_uhs2_block_count 32-bit
  [31:0] XFER_BLK_COUNT — This register is effective when Data Present is set to 1 in UHS-II Command register and is enabled when Block Count Enable is set to 1 and Block / Byte Mode is set to 0 in the UHS-II Transfer Mode register. Data transfer stops when the count reaches zero. Setting the block count to 0 results in no data blocks is transferred. This register should be accessed only when no transaction is executing [i.e.,after transactions are stopped]. During data transfer, read operations on this register may return an invalid value and write operations are ignored. 00000000h - Stop Count 00000001h - 1 block 00000002h - 2 blocks ..... ..... FFFFFFFFh - 4G blocks -1.
0x88 SDHC_WRAP__CTL_CFG__CTLCFG_uhs2_command_pkt 8-bit
  [7:0] CMD_PKT_BYTE — UHS-II Command Packet image is set to this register.The command length varies depends on a Command Packet type.
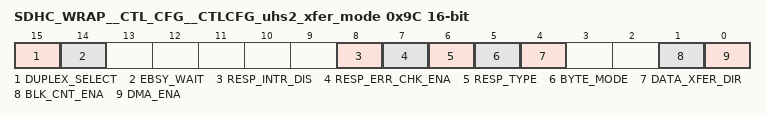
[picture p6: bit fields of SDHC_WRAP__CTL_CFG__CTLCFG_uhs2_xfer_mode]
0x9C SDHC_WRAP__CTL_CFG__CTLCFG_uhs2_xfer_mode
  [15] DUPLEX_SELECT — Use of 2 lane half duplex mode is determined by Host Driver.
  [14] EBSY_WAIT — This bit is set when issuing a command which is accompanied by EBSY packet to indicate end of command execution. Busy is expected for CCMD with R1b/R5b type and DCMD with data transfer.If this bit is set to 1, Host Controller waits receiving of EBSY packet and on receiving EBSY packet, Transfer Com-plete in the Normal Interrupt Status reg-ister is set to 1 to indicate end ofbusy. If an error is indicated in EBSY packet [ex. Memory Error], EBSY Error in the UHS-II Error Interrupt Status register is set to 1. Setting of EBSY Error also sets Error Interrupt to 1 in the Normal Inter-rupt Status register. Error Interrupt and Transfer Complete shall be set together. '1' Wait EBSY, '0' Issue a command without busy.
  [8] RESP_INTR_DIS — Host Controller Version 4.00 supports response error check function to avoid overhead of response error check by Host Driver. Only R1 or R5 can be checked. If Host Driver checks response error, sets this bit to 0 and waits Command Complete Interrupt and then check the response register. If Host Controller checks response error, sets this bit to 1 and sets Response Error Check Enable to 1. Command Complete Interrupt is disabled by this bit regardless of Com-mand Complete Signal Enable.
  [7] RESP_ERR_CHK_ENA — Host Controller Version 4.00 supports response error check function to avoid overhead of response error check by Host Driver.Only R1 or R5 can be checked. If Host Driver checks response error, this bit is set to 0 and Response Inter-rupt Disable is set to 0. If Host Control-ler checks response error, sets this bit to 1 and sets Response Interrupt Dis-able to 1. Response Type R1 / R5 selects either R1 or R5 response type. If an error is detected, RES Packet Error Interrupt is generated in the UHS-II Error Interrupt Status register.
  [6] RESP_TYPE — When response error check is enabled, this bit selects either R1 or R5 response types. Two types of response checks are supported: R1 for memory and R5 for SDIO. Error Statuses Checked in R1 Bit31 OUT_OF_RANGE Bit30 ADDRESS_ERROR Bit29 BLOCK_LEN_ERROR Bit26 WP_VIOLATION Bit25 CARD_IS_LOCKED Bit23 COM_CRC_ERROR Bit21 CARD_ECC_FAILED Bit20 CC_ERROR Bit19 ERROR Response Flags Checked in R5 .Bit07 COM_CRC_ERROR .Bit03 ERROR .Bit01 FUNCTION_NUMBER .Bit00 OUT_OF_RANGE
  [5] BYTE_MODE — This bit specifies whether data transfer is in byte mode or block mode when Data Present is set to 1. This bit is effective to a command with data trans-fer.
  [4] DATA_XFER_DIR — This bit specifies direction of data trans-fer when Data Present is set to 1. This bit is effective to a command with data transfer. 0 - Read [Card to Host] 1 - Write [Host to Card]
  [1] BLK_CNT_ENA — This bit specifies whether data transfer usesUHS-II Block Count register. If this bit is set to 1, data transfer is terminated by Block Count. Setting to UHS-II Block Count register shall be equivalent to TLEN in UHS-II Command Packet reg-ister.
  [0] DMA_ENA — This bit selects whether DMA is used or not and is effective to a command with data transfer. One of DMA types is selected by DMA Select in the Host Control 1 register.
